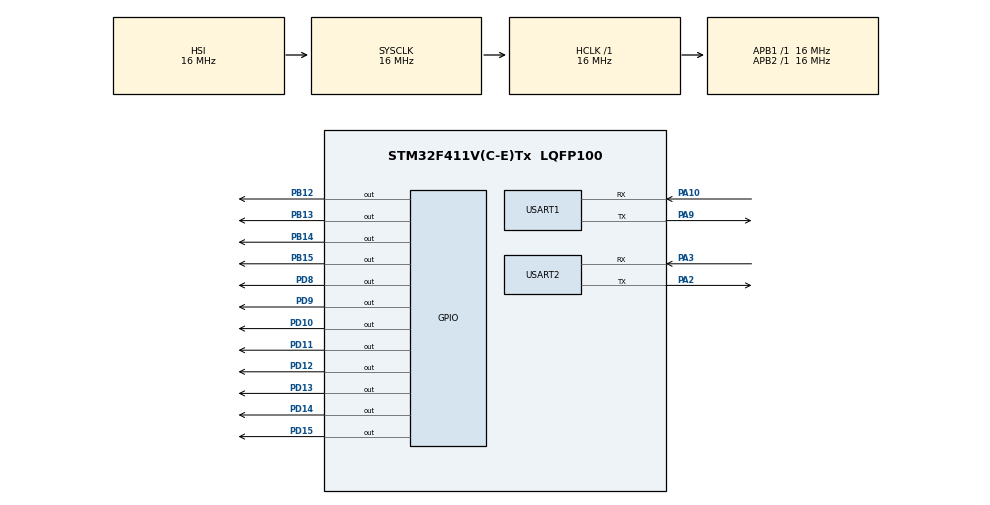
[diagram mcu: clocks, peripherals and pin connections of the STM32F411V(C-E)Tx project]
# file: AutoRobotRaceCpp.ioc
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Mcu.Family=STM32F4
Mcu.Name=STM32F411V(C-E)Tx
Mcu.Package=LQFP100
NVIC.PriorityGroup=NVIC_PRIORITYGROUP_4
NVIC.TIM2_IRQn=true\:0\:0\:false\:false\:true\:true\:true
PA10.Mode=Asynchronous
PA10.Signal=USART1_RX
PA13.Mode=Serial_Wire
PA13.Signal=SYS_JTMS-SWDIO
PA14.Mode=Serial_Wire
PA14.Signal=SYS_JTCK-SWCLK
PA2.Mode=Asynchronous
PA2.Signal=USART2_TX
PA3.Mode=Asynchronous
PA3.Signal=USART2_RX
PA9.Mode=Asynchronous
PA9.Signal=USART1_TX
PB12.Signal=GPIO_Output
PB13.Signal=GPIO_Output
PB14.Signal=GPIO_Output
PB15.Signal=GPIO_Output
PD10.Signal=GPIO_Output
PD11.Signal=GPIO_Output
PD12.Signal=GPIO_Output
PD13.Signal=GPIO_Output
PD14.Signal=GPIO_Output
PD15.Signal=GPIO_Output
PD8.Signal=GPIO_Output
PD9.Signal=GPIO_Output
ProjectManager.HeapSize=0x200
ProjectManager.StackSize=0x400
ProjectManager.TargetToolchain=STM32CubeIDE
RCC.AHBFreq_Value=16000000
RCC.APB1Freq_Value=16000000
RCC.APB2Freq_Value=16000000
RCC.CortexFreq_Value=16000000
RCC.HSE_VALUE=25000000
RCC.HSI_VALUE=16000000
RCC.LSE_VALUE=32768
RCC.SYSCLKFreq_VALUE=16000000
RCC.VCOOutputFreq_Value=192000000
TIM2.Period=99
TIM2.Prescaler=1599
USART1.VirtualMode=VM_ASYNC
USART2.VirtualMode=VM_ASYNC
VP_TIM2_VS_ClockSourceINT.Mode=Internal
board=custom

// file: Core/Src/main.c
/* USER CODE BEGIN Header */
/**
 ******************************************************************************
 * @file           : main.c
 * @brief          : Main program body
 ******************************************************************************
 * @attention
 *
 * <h2><center>&copy; Copyright (c) 2020 STMicroelectronics.
 * All rights reserved.</center></h2>
 *
 * This software component is licensed by ST under BSD 3-Clause license,
 * the "License"; You may not use this file except in compliance with the
 * License. You may obtain a copy of the License at:
 *                        opensource.org/licenses/BSD-3-Clause
 *
 ******************************************************************************
 */
/* USER CODE END Header */
#include "main.h"

/* USER CODE BEGIN Includes */
#include "Define.h"
#include "StepMotor.h"
#include "CallMain.h"
/* USER CODE END Includes */

TIM_HandleTypeDef htim2;

UART_HandleTypeDef huart1;
UART_HandleTypeDef huart2;

/* USER CODE BEGIN PV */
uint8_t Running; //if 1: running, 0: stop
/* USER CODE END PV */

void SystemClock_Config(void);
static void MX_GPIO_Init(void);
static void MX_USART1_UART_Init(void);
static void MX_USART2_UART_Init(void);
static void MX_TIM2_Init(void);
/* USER CODE BEGIN PFP */
void HAL_TIM_PeriodElapsedCallback(TIM_HandleTypeDef *htim){
//	HAL_GPIO_TogglePin(GPIOD, GPIO_PIN_15);
	if(Running){
		RunningCar();
	}
}
/* USER CODE END PFP */

int main(void)
{
  /* USER CODE BEGIN 1 */
	StepMotor M1, M2;
  /* USER CODE END 1 */

  /* MCU Configuration--------------------------------------------------------*/

  /* Reset of all peripherals, Initializes the Flash interface and the Systick. */
  HAL_Init();

  /* USER CODE BEGIN Init */
	InitAutoCar(&Running);
	SetM1Pin(&M1, 1); //Which value to pin Dir to make motor go ahead (1 or 0)
	SetM2Pin(&M2, 1); //Which value to pin Dir to make motor go ahead (1 or 0)
  /* USER CODE END Init */

  /* Configure the system clock */
  SystemClock_Config();

  /* USER CODE BEGIN SysInit */
  HAL_TIM_Base_Start_IT(&htim2);
  /* USER CODE END SysInit */

  /* Initialize all configured peripherals */
  MX_GPIO_Init();
  MX_USART1_UART_Init();
  MX_USART2_UART_Init();
  MX_TIM2_Init();
  /* USER CODE BEGIN 2 */
	HAL_TIM_Base_Start_IT(&htim2);
  /* USER CODE END 2 */

  /* Infinite loop */
	while (1) {

	}
}

void SystemClock_Config(void)
{
  RCC_OscInitTypeDef RCC_OscInitStruct = {0};
  RCC_ClkInitTypeDef RCC_ClkInitStruct = {0};

  /** Configure the main internal regulator output voltage
  */
  __HAL_RCC_PWR_CLK_ENABLE();
  __HAL_PWR_VOLTAGESCALING_CONFIG(PWR_REGULATOR_VOLTAGE_SCALE1);
  /** Initializes the RCC Oscillators according to the specified parameters
  * in the RCC_OscInitTypeDef structure.
  */
  RCC_OscInitStruct.OscillatorType = RCC_OSCILLATORTYPE_HSI;
  RCC_OscInitStruct.HSIState = RCC_HSI_ON;
  RCC_OscInitStruct.HSICalibrationValue = RCC_HSICALIBRATION_DEFAULT;
  RCC_OscInitStruct.PLL.PLLState = RCC_PLL_NONE;
  if (HAL_RCC_OscConfig(&RCC_OscInitStruct) != HAL_OK)
  {
    Error_Handler();
  }
  /** Initializes the CPU, AHB and APB buses clocks
  */
  RCC_ClkInitStruct.ClockType = RCC_CLOCKTYPE_HCLK|RCC_CLOCKTYPE_SYSCLK
                              |RCC_CLOCKTYPE_PCLK1|RCC_CLOCKTYPE_PCLK2;
  RCC_ClkInitStruct.SYSCLKSource = RCC_SYSCLKSOURCE_HSI;
  RCC_ClkInitStruct.AHBCLKDivider = RCC_SYSCLK_DIV1;
  RCC_ClkInitStruct.APB1CLKDivider = RCC_HCLK_DIV1;
  RCC_ClkInitStruct.APB2CLKDivider = RCC_HCLK_DIV1;

  if (HAL_RCC_ClockConfig(&RCC_ClkInitStruct, FLASH_LATENCY_0) != HAL_OK)
  {
    Error_Handler();
  }
}

static void MX_TIM2_Init(void)
{

  TIM_ClockConfigTypeDef sClockSourceConfig = {0};
  TIM_MasterConfigTypeDef sMasterConfig = {0};

  htim2.Instance = TIM2;
  htim2.Init.Prescaler = 1599;
  htim2.Init.CounterMode = TIM_COUNTERMODE_UP;
  htim2.Init.Period = 99;
  htim2.Init.ClockDivision = TIM_CLOCKDIVISION_DIV1;
  htim2.Init.AutoReloadPreload = TIM_AUTORELOAD_PRELOAD_DISABLE;
  if (HAL_TIM_Base_Init(&htim2) != HAL_OK)
  {
    Error_Handler();
  }
  sClockSourceConfig.ClockSource = TIM_CLOCKSOURCE_INTERNAL;
  if (HAL_TIM_ConfigClockSource(&htim2, &sClockSourceConfig) != HAL_OK)
  {
    Error_Handler();
  }
  sMasterConfig.MasterOutputTrigger = TIM_TRGO_RESET;
  sMasterConfig.MasterSlaveMode = TIM_MASTERSLAVEMODE_DISABLE;
  if (HAL_TIMEx_MasterConfigSynchronization(&htim2, &sMasterConfig) != HAL_OK)
  {
    Error_Handler();
  }

}

static void MX_USART1_UART_Init(void)
{

  huart1.Instance = USART1;
  huart1.Init.BaudRate = 115200;
  huart1.Init.WordLength = UART_WORDLENGTH_8B;
  huart1.Init.StopBits = UART_STOPBITS_1;
  huart1.Init.Parity = UART_PARITY_NONE;
  huart1.Init.Mode = UART_MODE_TX_RX;
  huart1.Init.HwFlowCtl = UART_HWCONTROL_NONE;
  huart1.Init.OverSampling = UART_OVERSAMPLING_16;
  if (HAL_UART_Init(&huart1) != HAL_OK)
  {
    Error_Handler();
  }

}

static void MX_USART2_UART_Init(void)
{

  huart2.Instance = USART2;
  huart2.Init.BaudRate = 115200;
  huart2.Init.WordLength = UART_WORDLENGTH_8B;
  huart2.Init.StopBits = UART_STOPBITS_1;
  huart2.Init.Parity = UART_PARITY_NONE;
  huart2.Init.Mode = UART_MODE_TX_RX;
  huart2.Init.HwFlowCtl = UART_HWCONTROL_NONE;
  huart2.Init.OverSampling = UART_OVERSAMPLING_16;
  if (HAL_UART_Init(&huart2) != HAL_OK)
  {
    Error_Handler();
  }

}

static void MX_GPIO_Init(void)
{
  GPIO_InitTypeDef GPIO_InitStruct = {0};

  /* GPIO Ports Clock Enable */
  __HAL_RCC_GPIOA_CLK_ENABLE();
  __HAL_RCC_GPIOB_CLK_ENABLE();
  __HAL_RCC_GPIOD_CLK_ENABLE();

  /*Configure GPIO pin Output Level */
  HAL_GPIO_WritePin(GPIOB, GPIO_PIN_12|GPIO_PIN_13|GPIO_PIN_14|GPIO_PIN_15, GPIO_PIN_RESET);

  /*Configure GPIO pin Output Level */
  HAL_GPIO_WritePin(GPIOD, GPIO_PIN_8|GPIO_PIN_9|GPIO_PIN_10|GPIO_PIN_11
                          |GPIO_PIN_12|GPIO_PIN_13|GPIO_PIN_14|GPIO_PIN_15, GPIO_PIN_RESET);

  /*Configure GPIO pins : PB12 PB13 PB14 PB15 */
  GPIO_InitStruct.Pin = GPIO_PIN_12|GPIO_PIN_13|GPIO_PIN_14|GPIO_PIN_15;
  GPIO_InitStruct.Mode = GPIO_MODE_OUTPUT_PP;
  GPIO_InitStruct.Pull = GPIO_NOPULL;
  GPIO_InitStruct.Speed = GPIO_SPEED_FREQ_LOW;
  HAL_GPIO_Init(GPIOB, &GPIO_InitStruct);

  /*Configure GPIO pins : PD8 PD9 PD10 PD11
                           PD12 PD13 PD14 PD15 */
  GPIO_InitStruct.Pin = GPIO_PIN_8|GPIO_PIN_9|GPIO_PIN_10|GPIO_PIN_11
                          |GPIO_PIN_12|GPIO_PIN_13|GPIO_PIN_14|GPIO_PIN_15;
  GPIO_InitStruct.Mode = GPIO_MODE_OUTPUT_PP;
  GPIO_InitStruct.Pull = GPIO_NOPULL;
  GPIO_InitStruct.Speed = GPIO_SPEED_FREQ_LOW;
  HAL_GPIO_Init(GPIOD, &GPIO_InitStruct);

}

void Error_Handler(void)
{
}

/************************ (C) COPYRIGHT STMicroelectronics *****END OF FILE****/
